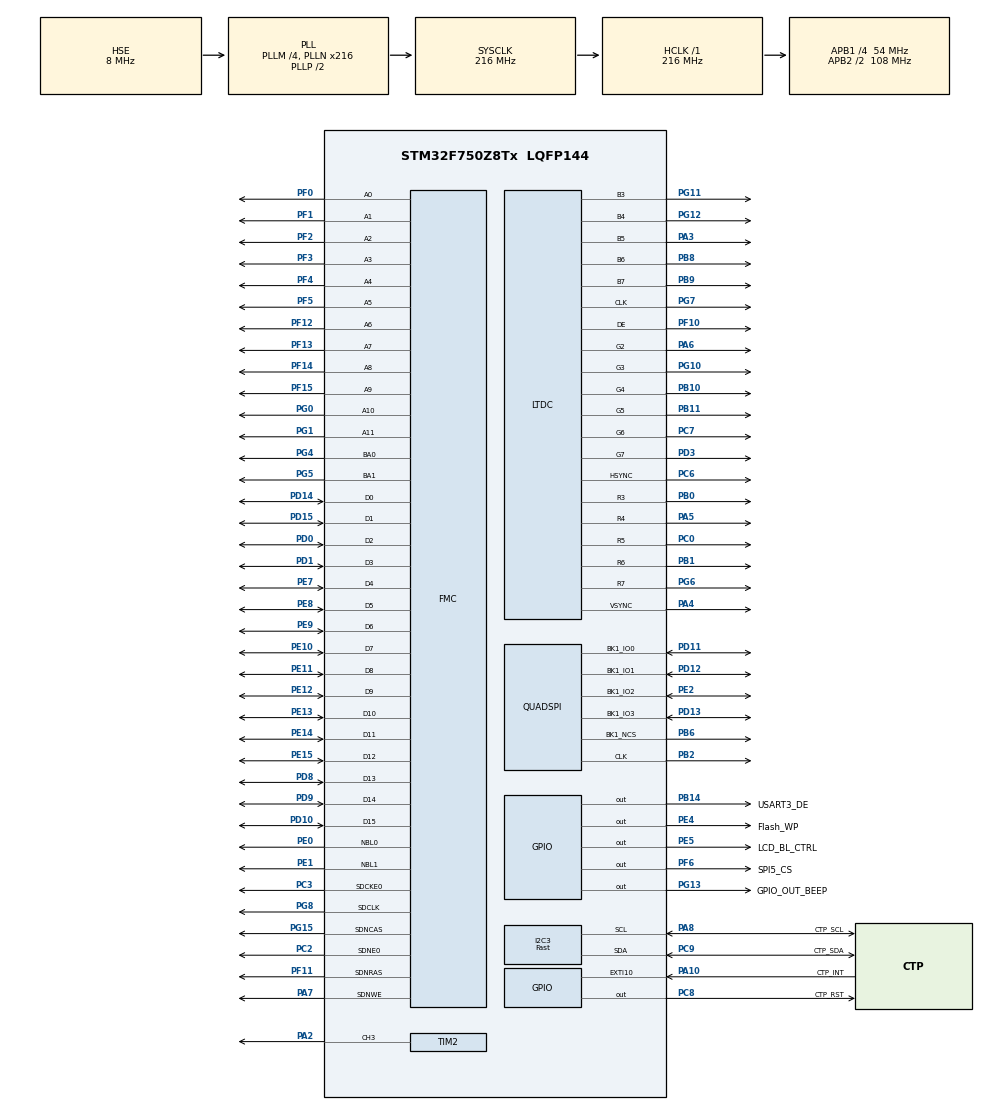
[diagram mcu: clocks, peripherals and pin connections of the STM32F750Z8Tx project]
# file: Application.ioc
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CORTEX_M7.ART_ACCLERATOR_ENABLE=1
CORTEX_M7.BaseAddress-Cortex_Memory_Protection_Unit_Region0_Settings=0xC0000000
CORTEX_M7.CPU_DCache=Enabled
CORTEX_M7.CPU_ICache=Enabled
CORTEX_M7.Enable-Cortex_Memory_Protection_Unit_Region0_Settings=MPU_REGION_ENABLE
CORTEX_M7.IsCacheable-Cortex_Memory_Protection_Unit_Region0_Settings=MPU_ACCESS_CACHEABLE
CORTEX_M7.IsShareable-Cortex_Memory_Protection_Unit_Region0_Settings=MPU_ACCESS_SHAREABLE
CORTEX_M7.MPU_Control=MPU_HFNMI_PRIVDEF
CORTEX_M7.Size-Cortex_Memory_Protection_Unit_Region0_Settings=MPU_REGION_SIZE_16MB
DMA2D.ColorMode=DMA2D_OUTPUT_RGB565
Dma.MEMTOMEM.1.Direction=DMA_MEMORY_TO_MEMORY
Dma.MEMTOMEM.1.FIFOMode=DMA_FIFOMODE_ENABLE
Dma.MEMTOMEM.1.FIFOThreshold=DMA_FIFO_THRESHOLD_FULL
Dma.MEMTOMEM.1.Instance=DMA2_Stream0
Dma.MEMTOMEM.1.MemBurst=DMA_MBURST_SINGLE
Dma.MEMTOMEM.1.MemDataAlignment=DMA_MDATAALIGN_BYTE
Dma.MEMTOMEM.1.MemInc=DMA_MINC_ENABLE
Dma.MEMTOMEM.1.Mode=DMA_NORMAL
Dma.MEMTOMEM.1.PeriphBurst=DMA_PBURST_SINGLE
Dma.MEMTOMEM.1.PeriphDataAlignment=DMA_PDATAALIGN_BYTE
Dma.MEMTOMEM.1.PeriphInc=DMA_PINC_ENABLE
Dma.MEMTOMEM.1.Priority=DMA_PRIORITY_LOW
Dma.QUADSPI.0.Direction=DMA_PERIPH_TO_MEMORY
Dma.QUADSPI.0.FIFOMode=DMA_FIFOMODE_DISABLE
Dma.QUADSPI.0.Instance=DMA2_Stream7
Dma.QUADSPI.0.MemDataAlignment=DMA_MDATAALIGN_BYTE
Dma.QUADSPI.0.MemInc=DMA_MINC_ENABLE
Dma.QUADSPI.0.Mode=DMA_NORMAL
Dma.QUADSPI.0.PeriphDataAlignment=DMA_PDATAALIGN_BYTE
Dma.QUADSPI.0.PeriphInc=DMA_PINC_DISABLE
Dma.QUADSPI.0.Priority=DMA_PRIORITY_HIGH
Dma.Request0=QUADSPI
Dma.Request1=MEMTOMEM
FMC.CASLatency1=FMC_SDRAM_CAS_LATENCY_3
FMC.ExitSelfRefreshDelay1=7
FMC.LoadToActiveDelay1=2
FMC.RCDDelay1=2
FMC.RPDelay1=2
FMC.RPDelay2=2
FMC.RowCycleDelay1=7
FMC.RowCycleDelay2=7
FMC.SelfRefreshTime1=4
FMC.WriteRecoveryTime1=3
FREERTOS.INCLUDE_vTaskDelayUntil=0
FREERTOS.Tasks01=defaultTask,24,4096,StartDefaultTask,Default,NULL,Dynamic,NULL,NULL
FREERTOS.configTOTAL_HEAP_SIZE=40960
FREERTOS.configUSE_IDLE_HOOK=0
FREERTOS.configUSE_TICK_HOOK=1
I2C3.I2C_Speed_Mode=I2C_Fast
I2C3.Timing=0x6000030D
LTDC.ActiveH=480
LTDC.ActiveW=800
LTDC.Alpha_L0=255
LTDC.DEPolarity=LTDC_DEPOLARITY_AL
LTDC.FBStartAdress_L0=0xC0500000
LTDC.HBP=8
LTDC.HFP=8
LTDC.HSync=4
LTDC.ImageHeight_L0=480
LTDC.ImageWidth_L0=800
LTDC.Layers=0
LTDC.PCPolarity=LTDC_PCPOLARITY_IPC
LTDC.PixelFormat_L0=LTDC_PIXEL_FORMAT_RGB565
LTDC.VBP=8
LTDC.VFP=8
LTDC.VSync=4
LTDC.WindowX1_L0=800
LTDC.WindowY1_L0=480
Mcu.Family=STM32F7
Mcu.Name=STM32F750Z8Tx
Mcu.Package=LQFP144
NVIC.DMA2D_IRQn=true\:5\:0\:true\:false\:true\:false\:true\:true
NVIC.DMA2_Stream7_IRQn=true\:5\:0\:true\:false\:true\:true\:false\:true
NVIC.I2C3_ER_IRQn=true\:5\:0\:true\:false\:true\:true\:true\:true
NVIC.I2C3_EV_IRQn=true\:5\:0\:true\:false\:true\:true\:true\:true
NVIC.LTDC_ER_IRQn=true\:5\:0\:true\:false\:true\:true\:true\:true
NVIC.LTDC_IRQn=true\:5\:0\:true\:false\:true\:true\:true\:true
NVIC.PriorityGroup=NVIC_PRIORITYGROUP_4
NVIC.TIM5_IRQn=true\:0\:0\:false\:false\:true\:false\:false\:true
NVIC.TIM7_IRQn=true\:5\:0\:true\:false\:true\:false\:true\:true
NVIC.TimeBase=TIM5_IRQn
NVIC.TimeBaseIP=TIM5
PA1.Signal=LTDC_R2
PA10.GPIO_Label=CTP_INT
PA10.Signal=GPXTI10
PA13.Mode=Serial_Wire
PA13.Signal=SYS_JTMS-SWDIO
PA14.Mode=Serial_Wire
PA14.Signal=SYS_JTCK-SWCLK
PA2.Signal=S_TIM2_CH3
PA3.GPIO_Speed=GPIO_SPEED_FREQ_VERY_HIGH
PA3.Mode=RGB565
PA3.Signal=LTDC_B5
PA4.GPIO_Speed=GPIO_SPEED_FREQ_VERY_HIGH
PA4.Mode=RGB565
PA4.Signal=LTDC_VSYNC
PA5.GPIO_Speed=GPIO_SPEED_FREQ_VERY_HIGH
PA5.Mode=RGB565
PA5.Signal=LTDC_R4
PA6.GPIO_Speed=GPIO_SPEED_FREQ_VERY_HIGH
PA6.Mode=RGB565
PA6.Signal=LTDC_G2
PA7.Signal=FMC_SDNWE
PA8.GPIO_Label=CTP_SCL
PA8.Mode=I2C
PA8.Signal=I2C3_SCL
PB0.GPIO_Speed=GPIO_SPEED_FREQ_VERY_HIGH
PB0.Mode=RGB565
PB0.Signal=LTDC_R3
PB1.GPIO_Speed=GPIO_SPEED_FREQ_VERY_HIGH
PB1.Mode=RGB565
PB1.Signal=LTDC_R6
PB10.GPIO_Speed=GPIO_SPEED_FREQ_VERY_HIGH
PB10.Mode=RGB565
PB10.Signal=LTDC_G4
PB11.GPIO_Speed=GPIO_SPEED_FREQ_VERY_HIGH
PB11.Mode=RGB565
PB11.Signal=LTDC_G5
PB14.GPIO_Label=USART3_DE
PB14.Signal=GPIO_Output
PB2.Mode=Single Bank 1
PB2.Signal=QUADSPI_CLK
PB6.Mode=Single Bank 1
PB6.Signal=QUADSPI_BK1_NCS
PB8.GPIO_Speed=GPIO_SPEED_FREQ_VERY_HIGH
PB8.Mode=RGB565
PB8.Signal=LTDC_B6
PB9.GPIO_Speed=GPIO_SPEED_FREQ_VERY_HIGH
PB9.Mode=RGB565
PB9.Signal=LTDC_B7
PC0.GPIO_Speed=GPIO_SPEED_FREQ_VERY_HIGH
PC0.Mode=RGB565
PC0.Signal=LTDC_R5
PC14/OSC32_IN.Mode=LSE-External-Oscillator
PC14/OSC32_IN.Signal=RCC_OSC32_IN
PC15/OSC32_OUT.Mode=LSE-External-Oscillator
PC15/OSC32_OUT.Signal=RCC_OSC32_OUT
PC2.Mode=SdramChipSelect1_1
PC2.Signal=FMC_SDNE0
PC3.Mode=SdramChipSelect1_1
PC3.Signal=FMC_SDCKE0
PC6.GPIO_Speed=GPIO_SPEED_FREQ_VERY_HIGH
PC6.Mode=RGB565
PC6.Signal=LTDC_HSYNC
PC7.GPIO_Speed=GPIO_SPEED_FREQ_VERY_HIGH
PC7.Mode=RGB565
PC7.Signal=LTDC_G6
PC8.GPIO_Label=CTP_RST
PC8.PinState=GPIO_PIN_SET
PC8.Signal=GPIO_Output
PC9.GPIO_Label=CTP_SDA
PC9.Mode=I2C
PC9.Signal=I2C3_SDA
PD0.Signal=FMC_D2_DA2
PD1.Signal=FMC_D3_DA3
PD10.Signal=FMC_D15_DA15
PD11.Mode=Single Bank 1
PD11.Signal=QUADSPI_BK1_IO0
PD12.Mode=Single Bank 1
PD12.Signal=QUADSPI_BK1_IO1
PD13.Mode=Single Bank 1
PD13.Signal=QUADSPI_BK1_IO3
PD14.Signal=FMC_D0_DA0
PD15.Signal=FMC_D1_DA1
PD3.GPIO_Speed=GPIO_SPEED_FREQ_VERY_HIGH
PD3.Mode=RGB565
PD3.Signal=LTDC_G7
PD6.Signal=LTDC_B2
PD8.Signal=FMC_D13_DA13
PD9.Signal=FMC_D14_DA14
PE0.Signal=FMC_NBL0
PE1.Signal=FMC_NBL1
PE10.Signal=FMC_D7_DA7
PE11.Signal=FMC_D8_DA8
PE12.Signal=FMC_D9_DA9
PE13.Signal=FMC_D10_DA10
PE14.Signal=FMC_D11_DA11
PE15.Signal=FMC_D12_DA12
PE2.Mode=Single Bank 1
PE2.Signal=QUADSPI_BK1_IO2
PE4.GPIO_Label=Flash_WP
PE4.PinState=GPIO_PIN_RESET
PE4.Signal=GPIO_Output
PE5.GPIO_Label=LCD_BL_CTRL
PE5.PinState=GPIO_PIN_RESET
PE5.Signal=GPIO_Output
PE7.Signal=FMC_D4_DA4
PE8.Signal=FMC_D5_DA5
PE9.Signal=FMC_D6_DA6
PF0.Signal=FMC_A0
PF1.Signal=FMC_A1
PF10.GPIO_PuPd=GPIO_NOPULL
PF10.GPIO_Speed=GPIO_SPEED_FREQ_VERY_HIGH
PF10.Mode=RGB565
PF10.Signal=LTDC_DE
PF11.Signal=FMC_SDNRAS
PF12.Signal=FMC_A6
PF13.Signal=FMC_A7
PF14.Signal=FMC_A8
PF15.Signal=FMC_A9
PF2.Signal=FMC_A2
PF3.Signal=FMC_A3
PF4.Signal=FMC_A4
PF5.Signal=FMC_A5
PF6.GPIO_Label=SPI5_CS
PF6.GPIO_Speed=GPIO_SPEED_FREQ_HIGH
PF6.Signal=GPIO_Output
PG0.Signal=FMC_A10
PG1.Signal=FMC_A11
PG10.GPIO_Speed=GPIO_SPEED_FREQ_VERY_HIGH
PG10.Mode=RGB565
PG10.Signal=LTDC_G3
PG11.GPIO_Speed=GPIO_SPEED_FREQ_VERY_HIGH
PG11.Mode=RGB565
PG11.Signal=LTDC_B3
PG12.GPIO_Speed=GPIO_SPEED_FREQ_VERY_HIGH
PG12.Mode=RGB565
PG12.Signal=LTDC_B4
PG13.GPIO_Label=GPIO_OUT_BEEP
PG13.Signal=GPIO_Output
PG15.Signal=FMC_SDNCAS
PG4.Signal=FMC_A14_BA0
PG5.Signal=FMC_A15_BA1
PG6.GPIO_Speed=GPIO_SPEED_FREQ_VERY_HIGH
PG6.Mode=RGB565
PG6.Signal=LTDC_R7
PG7.GPIO_Speed=GPIO_SPEED_FREQ_VERY_HIGH
PG7.Mode=RGB565
PG7.Signal=LTDC_CLK
PG8.Signal=FMC_SDCLK
PH0/OSC_IN.Mode=HSE-External-Oscillator
PH0/OSC_IN.Signal=RCC_OSC_IN
PH1/OSC_OUT.Mode=HSE-External-Oscillator
PH1/OSC_OUT.Signal=RCC_OSC_OUT
ProjectManager.HeapSize=0x1000
ProjectManager.StackSize=0x1000
ProjectManager.TargetToolchain=STM32CubeIDE
QUADSPI.ChipSelectHighTime=QSPI_CS_HIGH_TIME_2_CYCLE
QUADSPI.ClockPrescaler=3
QUADSPI.FifoThreshold=4
QUADSPI.FlashSize=16
QUADSPI.SampleShifting=QSPI_SAMPLE_SHIFTING_HALFCYCLE
RCC.AHBFreq_Value=216000000
RCC.APB1CLKDivider=RCC_HCLK_DIV4
RCC.APB1Freq_Value=54000000
RCC.APB1TimFreq_Value=108000000
RCC.APB2CLKDivider=RCC_HCLK_DIV2
RCC.APB2Freq_Value=108000000
RCC.APB2TimFreq_Value=216000000
RCC.CortexFreq_Value=216000000
RCC.HCLKFreq_Value=216000000
RCC.HSE_VALUE=8000000
RCC.HSI_VALUE=16000000
RCC.PLLM=4
RCC.PLLN=216
RCC.PLLSAIN=69
RCC.PLLSAIR=3
RCC.PLLSourceVirtual=RCC_PLLSOURCE_HSE
RCC.RTCClockSelection=RCC_RTCCLKSOURCE_LSE
RCC.SYSCLKFreq_VALUE=216000000
RCC.SYSCLKSource=RCC_SYSCLKSOURCE_PLLCLK
RCC.USBFreq_Value=216000000
RCC.VCOOutputFreq_Value=432000000
SH.FMC_A0.0=FMC_A0,12b-sda1
SH.FMC_A1.0=FMC_A1,12b-sda1
SH.FMC_A10.0=FMC_A10,12b-sda1
SH.FMC_A11.0=FMC_A11,12b-sda1
SH.FMC_A14_BA0.0=FMC_BA0,FourSdramBanks1
SH.FMC_A15_BA1.0=FMC_BA1,FourSdramBanks1
SH.FMC_A2.0=FMC_A2,12b-sda1
SH.FMC_A3.0=FMC_A3,12b-sda1
SH.FMC_A4.0=FMC_A4,12b-sda1
SH.FMC_A5.0=FMC_A5,12b-sda1
SH.FMC_A6.0=FMC_A6,12b-sda1
SH.FMC_A7.0=FMC_A7,12b-sda1
SH.FMC_A8.0=FMC_A8,12b-sda1
SH.FMC_A9.0=FMC_A9,12b-sda1
SH.FMC_D0_DA0.0=FMC_D0,sd-16b-d1
SH.FMC_D10_DA10.0=FMC_D10,sd-16b-d1
SH.FMC_D11_DA11.0=FMC_D11,sd-16b-d1
SH.FMC_D12_DA12.0=FMC_D12,sd-16b-d1
SH.FMC_D13_DA13.0=FMC_D13,sd-16b-d1
SH.FMC_D14_DA14.0=FMC_D14,sd-16b-d1
SH.FMC_D15_DA15.0=FMC_D15,sd-16b-d1
SH.FMC_D1_DA1.0=FMC_D1,sd-16b-d1
SH.FMC_D2_DA2.0=FMC_D2,sd-16b-d1
SH.FMC_D3_DA3.0=FMC_D3,sd-16b-d1
SH.FMC_D4_DA4.0=FMC_D4,sd-16b-d1
SH.FMC_D5_DA5.0=FMC_D5,sd-16b-d1
SH.FMC_D6_DA6.0=FMC_D6,sd-16b-d1
SH.FMC_D7_DA7.0=FMC_D7,sd-16b-d1
SH.FMC_D8_DA8.0=FMC_D8,sd-16b-d1
SH.FMC_D9_DA9.0=FMC_D9,sd-16b-d1
SH.FMC_NBL0.0=FMC_NBL0,Sd2ByteEnable1
SH.FMC_NBL1.0=FMC_NBL1,Sd2ByteEnable1
SH.FMC_SDCLK.0=FMC_SDCLK,12b-sda1
SH.FMC_SDNCAS.0=FMC_SDNCAS,12b-sda1
SH.FMC_SDNRAS.0=FMC_SDNRAS,12b-sda1
SH.FMC_SDNWE.0=FMC_SDNWE,12b-sda1
SH.S_TIM2_CH3.0=TIM2_CH3,PWM Generation3 CH3
STMicroelectronics.X-CUBE-TOUCHGFX.4.16.0.ApplicationCcGraphicsJjApplication=TouchGFXOoGenerator
STMicroelectronics.X-CUBE-TOUCHGFX.4.16.0.tgfx_address1=0xc0500000
STMicroelectronics.X-CUBE-TOUCHGFX.4.16.0.tgfx_address2=0xc05bb800
STMicroelectronics.X-CUBE-TOUCHGFX.4.16.0.tgfx_buffering_strategy=Double
STMicroelectronics.X-CUBE-TOUCHGFX.4.16.0.tgfx_custom_height=128
STMicroelectronics.X-CUBE-TOUCHGFX.4.16.0.tgfx_display_interface=disp_ltdc
STMicroelectronics.X-CUBE-TOUCHGFX.4.16.0.tgfx_hardware_accelerator=dma_2d
STMicroelectronics.X-CUBE-TOUCHGFX.4.16.0.tgfx_location=By Address
STMicroelectronics.X-CUBE-TOUCHGFX.4.16.0.tgfx_vsync=vsync_ltdc
TIM2.AutoReloadPreload=TIM_AUTORELOAD_PRELOAD_ENABLE
TIM2.Channel-PWM\ Generation3\ CH3=TIM_CHANNEL_3
TIM2.Period=99
TIM2.Prescaler=54-1
TIM7.Period=0
VP_CRC_VS_CRC.Mode=CRC_Activate
VP_DMA2D_VS_DMA2D.Mode=DMA2D_Activate
VP_FREERTOS_VS_CMSIS_V2.Mode=CMSIS_V2
VP_STMicroelectronics.X-CUBE-TOUCHGFX_VS_GraphicsJjApplication_4.16.0.Mode=GraphicsJjApplication
VP_SYS_VS_tim5.Mode=TIM5
VP_TIM7_VS_ClockSourceINT.Mode=Enable_Timer
board=custom

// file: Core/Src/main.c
/* USER CODE BEGIN Header */
/**
  ******************************************************************************
  * @file           : main.c
  * @brief          : Main program body
  ******************************************************************************
  * @attention
  *
  * <h2><center>&copy; Copyright (c) 2023 STMicroelectronics.
  * All rights reserved.</center></h2>
  *
  * This software component is licensed by ST under Ultimate Liberty license
  * SLA0044, the "License"; You may not use this file except in compliance with
  * the License. You may obtain a copy of the License at:
  *                             www.st.com/SLA0044
  *
  ******************************************************************************
  */
/* USER CODE END Header */
#include "main.h"
#include "cmsis_os.h"
#include "app_touchgfx.h"

/* USER CODE BEGIN PD */
#define ADDR_DISPLAY_MEM    ((uint32_t)0xC0500000)
/* USER CODE END PD */

CRC_HandleTypeDef hcrc;

DMA2D_HandleTypeDef hdma2d;

I2C_HandleTypeDef hi2c3;

LTDC_HandleTypeDef hltdc;

QSPI_HandleTypeDef hqspi;
DMA_HandleTypeDef hdma_quadspi;

TIM_HandleTypeDef htim2;
TIM_HandleTypeDef htim7;

DMA_HandleTypeDef hdma_memtomem_dma2_stream0;
SDRAM_HandleTypeDef hsdram1;

/* Definitions for defaultTask */
osThreadId_t defaultTaskHandle;
const osThreadAttr_t defaultTask_attributes = {
  .name = "defaultTask",
  .priority = (osPriority_t) osPriorityNormal,
  .stack_size = 4096 * 4
};

void SystemClock_Config(void);
static void MPU_Config(void);
static void MX_GPIO_Init(void);
static void MX_DMA_Init(void);
static void MX_QUADSPI_Init(void);
static void MX_DMA2D_Init(void);
static void MX_LTDC_Init(void);
static void MX_CRC_Init(void);
static void MX_FMC_Init(void);
static void MX_TIM7_Init(void);
static void MX_I2C3_Init(void);
static void MX_TIM2_Init(void);
void StartDefaultTask(void *argument);

/* USER CODE BEGIN 0 */
void Reset_Ressource(void)
{
  /*DeInit LCD Ressource*/
  __HAL_RCC_LTDC_CLK_DISABLE();
  __HAL_RCC_LTDC_FORCE_RESET();
  __HAL_RCC_LTDC_RELEASE_RESET();
  __HAL_RCC_PLLSAI_DISABLE();
  RCC->DCKCFGR1 = 0;
  RCC->PLLSAICFGR &= 0x0FFFFFFF;
  RCC->PLLSAICFGR |= 0x20000000;
}
/* USER CODE END 0 */

int main(void)
{
  /* USER CODE BEGIN 1 */
	memset((void *)ADDR_DISPLAY_MEM, 0x00, 800*480*2); //RESET
	Reset_Ressource();
  /* USER CODE END 1 */

  /* MPU Configuration--------------------------------------------------------*/
  MPU_Config();

  /* Enable I-Cache---------------------------------------------------------*/
  SCB_EnableICache();

  /* Enable D-Cache---------------------------------------------------------*/
  SCB_EnableDCache();

  /* MCU Configuration--------------------------------------------------------*/

  /* Reset of all peripherals, Initializes the Flash interface and the Systick. */
  HAL_Init();

  /* Configure the system clock */
  SystemClock_Config();

  /* Initialize all configured peripherals */
  MX_GPIO_Init();
  MX_DMA_Init();
  MX_QUADSPI_Init();
  MX_DMA2D_Init();
  MX_LTDC_Init();
  MX_CRC_Init();
  MX_FMC_Init();
  MX_TIM7_Init();
  MX_I2C3_Init();
  MX_TIM2_Init();
  MX_TouchGFX_Init();
  /* USER CODE BEGIN 2 */
  memset((void *)ADDR_DISPLAY_MEM, 0x00, 800*480*2); //RESET
  HAL_GPIO_WritePin(GPIOE, Flash_WP_Pin|LCD_BL_CTRL_Pin, GPIO_PIN_SET);
  /* USER CODE END 2 */

  /* Init scheduler */
  osKernelInitialize();

  /* Create the thread(s) */
  /* creation of defaultTask */
  defaultTaskHandle = osThreadNew(StartDefaultTask, NULL, &defaultTask_attributes);

  /* Start scheduler */
  osKernelStart();

  /* We should never get here as control is now taken by the scheduler */
  /* Infinite loop */
  while (1)
  {

  }
}

void SystemClock_Config(void)
{
  RCC_OscInitTypeDef RCC_OscInitStruct = {0};
  RCC_ClkInitTypeDef RCC_ClkInitStruct = {0};
  RCC_PeriphCLKInitTypeDef PeriphClkInitStruct = {0};

  /** Configure LSE Drive Capability
  */
  HAL_PWR_EnableBkUpAccess();
  /** Configure the main internal regulator output voltage
  */
  __HAL_RCC_PWR_CLK_ENABLE();
  __HAL_PWR_VOLTAGESCALING_CONFIG(PWR_REGULATOR_VOLTAGE_SCALE1);
  /** Initializes the RCC Oscillators according to the specified parameters
  * in the RCC_OscInitTypeDef structure.
  */
  RCC_OscInitStruct.OscillatorType = RCC_OSCILLATORTYPE_HSE;
  RCC_OscInitStruct.HSEState = RCC_HSE_ON;
  RCC_OscInitStruct.PLL.PLLState = RCC_PLL_ON;
  RCC_OscInitStruct.PLL.PLLSource = RCC_PLLSOURCE_HSE;
  RCC_OscInitStruct.PLL.PLLM = 4;
  RCC_OscInitStruct.PLL.PLLN = 216;
  RCC_OscInitStruct.PLL.PLLP = RCC_PLLP_DIV2;
  RCC_OscInitStruct.PLL.PLLQ = 2;
  if (HAL_RCC_OscConfig(&RCC_OscInitStruct) != HAL_OK)
  {
    Error_Handler();
  }
  /** Activate the Over-Drive mode
  */
  if (HAL_PWREx_EnableOverDrive() != HAL_OK)
  {
    Error_Handler();
  }
  /** Initializes the CPU, AHB and APB buses clocks
  */
  RCC_ClkInitStruct.ClockType = RCC_CLOCKTYPE_HCLK|RCC_CLOCKTYPE_SYSCLK
                              |RCC_CLOCKTYPE_PCLK1|RCC_CLOCKTYPE_PCLK2;
  RCC_ClkInitStruct.SYSCLKSource = RCC_SYSCLKSOURCE_PLLCLK;
  RCC_ClkInitStruct.AHBCLKDivider = RCC_SYSCLK_DIV1;
  RCC_ClkInitStruct.APB1CLKDivider = RCC_HCLK_DIV4;
  RCC_ClkInitStruct.APB2CLKDivider = RCC_HCLK_DIV2;

  if (HAL_RCC_ClockConfig(&RCC_ClkInitStruct, FLASH_LATENCY_7) != HAL_OK)
  {
    Error_Handler();
  }
  PeriphClkInitStruct.PeriphClockSelection = RCC_PERIPHCLK_LTDC|RCC_PERIPHCLK_I2C3;
  PeriphClkInitStruct.PLLSAI.PLLSAIN = 69;
  PeriphClkInitStruct.PLLSAI.PLLSAIR = 3;
  PeriphClkInitStruct.PLLSAI.PLLSAIQ = 2;
  PeriphClkInitStruct.PLLSAI.PLLSAIP = RCC_PLLSAIP_DIV2;
  PeriphClkInitStruct.PLLSAIDivQ = 1;
  PeriphClkInitStruct.PLLSAIDivR = RCC_PLLSAIDIVR_2;
  PeriphClkInitStruct.I2c3ClockSelection = RCC_I2C3CLKSOURCE_PCLK1;
  if (HAL_RCCEx_PeriphCLKConfig(&PeriphClkInitStruct) != HAL_OK)
  {
    Error_Handler();
  }
}

static void MX_CRC_Init(void)
{

  hcrc.Instance = CRC;
  hcrc.Init.DefaultPolynomialUse = DEFAULT_POLYNOMIAL_ENABLE;
  hcrc.Init.DefaultInitValueUse = DEFAULT_INIT_VALUE_ENABLE;
  hcrc.Init.InputDataInversionMode = CRC_INPUTDATA_INVERSION_NONE;
  hcrc.Init.OutputDataInversionMode = CRC_OUTPUTDATA_INVERSION_DISABLE;
  hcrc.InputDataFormat = CRC_INPUTDATA_FORMAT_BYTES;
  if (HAL_CRC_Init(&hcrc) != HAL_OK)
  {
    Error_Handler();
  }

}

static void MX_DMA2D_Init(void)
{

  hdma2d.Instance = DMA2D;
  hdma2d.Init.Mode = DMA2D_M2M;
  hdma2d.Init.ColorMode = DMA2D_OUTPUT_RGB565;
  hdma2d.Init.OutputOffset = 0;
  hdma2d.LayerCfg[1].InputOffset = 0;
  hdma2d.LayerCfg[1].InputColorMode = DMA2D_INPUT_RGB565;
  hdma2d.LayerCfg[1].AlphaMode = DMA2D_NO_MODIF_ALPHA;
  hdma2d.LayerCfg[1].InputAlpha = 0;
  if (HAL_DMA2D_Init(&hdma2d) != HAL_OK)
  {
    Error_Handler();
  }
  if (HAL_DMA2D_ConfigLayer(&hdma2d, 1) != HAL_OK)
  {
    Error_Handler();
  }

}

static void MX_I2C3_Init(void)
{

  hi2c3.Instance = I2C3;
  hi2c3.Init.Timing = 0x6000030D;
  hi2c3.Init.OwnAddress1 = 0;
  hi2c3.Init.AddressingMode = I2C_ADDRESSINGMODE_7BIT;
  hi2c3.Init.DualAddressMode = I2C_DUALADDRESS_DISABLE;
  hi2c3.Init.OwnAddress2 = 0;
  hi2c3.Init.OwnAddress2Masks = I2C_OA2_NOMASK;
  hi2c3.Init.GeneralCallMode = I2C_GENERALCALL_DISABLE;
  hi2c3.Init.NoStretchMode = I2C_NOSTRETCH_DISABLE;
  if (HAL_I2C_Init(&hi2c3) != HAL_OK)
  {
    Error_Handler();
  }
  /** Configure Analogue filter
  */
  if (HAL_I2CEx_ConfigAnalogFilter(&hi2c3, I2C_ANALOGFILTER_ENABLE) != HAL_OK)
  {
    Error_Handler();
  }
  /** Configure Digital filter
  */
  if (HAL_I2CEx_ConfigDigitalFilter(&hi2c3, 0) != HAL_OK)
  {
    Error_Handler();
  }

}

static void MX_LTDC_Init(void)
{

  LTDC_LayerCfgTypeDef pLayerCfg = {0};
  LTDC_LayerCfgTypeDef pLayerCfg1 = {0};

  hltdc.Instance = LTDC;
  hltdc.Init.HSPolarity = LTDC_HSPOLARITY_AL;
  hltdc.Init.VSPolarity = LTDC_VSPOLARITY_AL;
  hltdc.Init.DEPolarity = LTDC_DEPOLARITY_AL;
  hltdc.Init.PCPolarity = LTDC_PCPOLARITY_IPC;
  hltdc.Init.HorizontalSync = 3;
  hltdc.Init.VerticalSync = 3;
  hltdc.Init.AccumulatedHBP = 11;
  hltdc.Init.AccumulatedVBP = 11;
  hltdc.Init.AccumulatedActiveW = 811;
  hltdc.Init.AccumulatedActiveH = 491;
  hltdc.Init.TotalWidth = 819;
  hltdc.Init.TotalHeigh = 499;
  hltdc.Init.Backcolor.Blue = 0;
  hltdc.Init.Backcolor.Green = 0;
  hltdc.Init.Backcolor.Red = 0;
  if (HAL_LTDC_Init(&hltdc) != HAL_OK)
  {
    Error_Handler();
  }
  pLayerCfg.WindowX0 = 0;
  pLayerCfg.WindowX1 = 800;
  pLayerCfg.WindowY0 = 0;
  pLayerCfg.WindowY1 = 480;
  pLayerCfg.PixelFormat = LTDC_PIXEL_FORMAT_RGB565;
  pLayerCfg.Alpha = 255;
  pLayerCfg.Alpha0 = 0;
  pLayerCfg.BlendingFactor1 = LTDC_BLENDING_FACTOR1_CA;
  pLayerCfg.BlendingFactor2 = LTDC_BLENDING_FACTOR2_CA;
  pLayerCfg.FBStartAdress = 0xC0500000;
  pLayerCfg.ImageWidth = 800;
  pLayerCfg.ImageHeight = 480;
  pLayerCfg.Backcolor.Blue = 0;
  pLayerCfg.Backcolor.Green = 0;
  pLayerCfg.Backcolor.Red = 0;
  if (HAL_LTDC_ConfigLayer(&hltdc, &pLayerCfg, 0) != HAL_OK)
  {
    Error_Handler();
  }
  pLayerCfg1.WindowX0 = 0;
  pLayerCfg1.WindowX1 = 0;
  pLayerCfg1.WindowY0 = 0;
  pLayerCfg1.WindowY1 = 0;
  pLayerCfg1.Alpha = 0;
  pLayerCfg1.Alpha0 = 0;
  pLayerCfg1.BlendingFactor1 = LTDC_BLENDING_FACTOR1_CA;
  pLayerCfg1.BlendingFactor2 = LTDC_BLENDING_FACTOR2_CA;
  pLayerCfg1.FBStartAdress = 0;
  pLayerCfg1.ImageWidth = 0;
  pLayerCfg1.ImageHeight = 0;
  pLayerCfg1.Backcolor.Blue = 0;
  pLayerCfg1.Backcolor.Green = 0;
  pLayerCfg1.Backcolor.Red = 0;
  if (HAL_LTDC_ConfigLayer(&hltdc, &pLayerCfg1, 1) != HAL_OK)
  {
    Error_Handler();
  }

}

static void MX_QUADSPI_Init(void)
{

  /* USER CODE BEGIN QUADSPI_Init 0 */
	return;
  /* USER CODE END QUADSPI_Init 0 */

  /* QUADSPI parameter configuration*/
  hqspi.Instance = QUADSPI;
  hqspi.Init.ClockPrescaler = 3;
  hqspi.Init.FifoThreshold = 4;
  hqspi.Init.SampleShifting = QSPI_SAMPLE_SHIFTING_HALFCYCLE;
  hqspi.Init.FlashSize = 16;
  hqspi.Init.ChipSelectHighTime = QSPI_CS_HIGH_TIME_2_CYCLE;
  hqspi.Init.ClockMode = QSPI_CLOCK_MODE_0;
  hqspi.Init.FlashID = QSPI_FLASH_ID_1;
  hqspi.Init.DualFlash = QSPI_DUALFLASH_DISABLE;
  if (HAL_QSPI_Init(&hqspi) != HAL_OK)
  {
    Error_Handler();
  }

}

static void MX_TIM2_Init(void)
{

  TIM_MasterConfigTypeDef sMasterConfig = {0};
  TIM_OC_InitTypeDef sConfigOC = {0};

  htim2.Instance = TIM2;
  htim2.Init.Prescaler = 54-1;
  htim2.Init.CounterMode = TIM_COUNTERMODE_UP;
  htim2.Init.Period = 99;
  htim2.Init.ClockDivision = TIM_CLOCKDIVISION_DIV1;
  htim2.Init.AutoReloadPreload = TIM_AUTORELOAD_PRELOAD_ENABLE;
  if (HAL_TIM_PWM_Init(&htim2) != HAL_OK)
  {
    Error_Handler();
  }
  sMasterConfig.MasterOutputTrigger = TIM_TRGO_RESET;
  sMasterConfig.MasterSlaveMode = TIM_MASTERSLAVEMODE_DISABLE;
  if (HAL_TIMEx_MasterConfigSynchronization(&htim2, &sMasterConfig) != HAL_OK)
  {
    Error_Handler();
  }
  sConfigOC.OCMode = TIM_OCMODE_PWM1;
  sConfigOC.Pulse = 0;
  sConfigOC.OCPolarity = TIM_OCPOLARITY_HIGH;
  sConfigOC.OCFastMode = TIM_OCFAST_DISABLE;
  if (HAL_TIM_PWM_ConfigChannel(&htim2, &sConfigOC, TIM_CHANNEL_3) != HAL_OK)
  {
    Error_Handler();
  }
  HAL_TIM_MspPostInit(&htim2);

}

static void MX_TIM7_Init(void)
{

  /* USER CODE BEGIN TIM7_Init 0 */
	return;
  /* USER CODE END TIM7_Init 0 */

  TIM_MasterConfigTypeDef sMasterConfig = {0};

  htim7.Instance = TIM7;
  htim7.Init.Prescaler = 0;
  htim7.Init.CounterMode = TIM_COUNTERMODE_UP;
  htim7.Init.Period = 0;
  htim7.Init.AutoReloadPreload = TIM_AUTORELOAD_PRELOAD_DISABLE;
  if (HAL_TIM_Base_Init(&htim7) != HAL_OK)
  {
    Error_Handler();
  }
  sMasterConfig.MasterOutputTrigger = TIM_TRGO_RESET;
  sMasterConfig.MasterSlaveMode = TIM_MASTERSLAVEMODE_DISABLE;
  if (HAL_TIMEx_MasterConfigSynchronization(&htim7, &sMasterConfig) != HAL_OK)
  {
    Error_Handler();
  }

}

static void MX_DMA_Init(void)
{

  /* DMA controller clock enable */
  __HAL_RCC_DMA2_CLK_ENABLE();

  /* Configure DMA request hdma_memtomem_dma2_stream0 on DMA2_Stream0 */
  hdma_memtomem_dma2_stream0.Instance = DMA2_Stream0;
  hdma_memtomem_dma2_stream0.Init.Channel = DMA_CHANNEL_0;
  hdma_memtomem_dma2_stream0.Init.Direction = DMA_MEMORY_TO_MEMORY;
  hdma_memtomem_dma2_stream0.Init.PeriphInc = DMA_PINC_ENABLE;
  hdma_memtomem_dma2_stream0.Init.MemInc = DMA_MINC_ENABLE;
  hdma_memtomem_dma2_stream0.Init.PeriphDataAlignment = DMA_PDATAALIGN_BYTE;
  hdma_memtomem_dma2_stream0.Init.MemDataAlignment = DMA_MDATAALIGN_BYTE;
  hdma_memtomem_dma2_stream0.Init.Mode = DMA_NORMAL;
  hdma_memtomem_dma2_stream0.Init.Priority = DMA_PRIORITY_LOW;
  hdma_memtomem_dma2_stream0.Init.FIFOMode = DMA_FIFOMODE_ENABLE;
  hdma_memtomem_dma2_stream0.Init.FIFOThreshold = DMA_FIFO_THRESHOLD_FULL;
  hdma_memtomem_dma2_stream0.Init.MemBurst = DMA_MBURST_SINGLE;
  hdma_memtomem_dma2_stream0.Init.PeriphBurst = DMA_PBURST_SINGLE;
  if (HAL_DMA_Init(&hdma_memtomem_dma2_stream0) != HAL_OK)
  {
    Error_Handler( );
  }

  /* DMA interrupt init */
  /* DMA2_Stream7_IRQn interrupt configuration */
  HAL_NVIC_SetPriority(DMA2_Stream7_IRQn, 5, 0);
  HAL_NVIC_EnableIRQ(DMA2_Stream7_IRQn);

}

/* FMC initialization function */
static void MX_FMC_Init(void)
{

  /* USER CODE BEGIN FMC_Init 0 */
	return;
  /* USER CODE END FMC_Init 0 */

  FMC_SDRAM_TimingTypeDef SdramTiming = {0};

  /** Perform the SDRAM1 memory initialization sequence
  */
  hsdram1.Instance = FMC_SDRAM_DEVICE;
  /* hsdram1.Init */
  hsdram1.Init.SDBank = FMC_SDRAM_BANK1;
  hsdram1.Init.ColumnBitsNumber = FMC_SDRAM_COLUMN_BITS_NUM_8;
  hsdram1.Init.RowBitsNumber = FMC_SDRAM_ROW_BITS_NUM_12;
  hsdram1.Init.MemoryDataWidth = FMC_SDRAM_MEM_BUS_WIDTH_16;
  hsdram1.Init.InternalBankNumber = FMC_SDRAM_INTERN_BANKS_NUM_4;
  hsdram1.Init.CASLatency = FMC_SDRAM_CAS_LATENCY_3;
  hsdram1.Init.WriteProtection = FMC_SDRAM_WRITE_PROTECTION_DISABLE;
  hsdram1.Init.SDClockPeriod = FMC_SDRAM_CLOCK_DISABLE;
  hsdram1.Init.ReadBurst = FMC_SDRAM_RBURST_DISABLE;
  hsdram1.Init.ReadPipeDelay = FMC_SDRAM_RPIPE_DELAY_0;
  /* SdramTiming */
  SdramTiming.LoadToActiveDelay = 2;
  SdramTiming.ExitSelfRefreshDelay = 7;
  SdramTiming.SelfRefreshTime = 4;
  SdramTiming.RowCycleDelay = 7;
  SdramTiming.WriteRecoveryTime = 3;
  SdramTiming.RPDelay = 2;
  SdramTiming.RCDDelay = 2;

  if (HAL_SDRAM_Init(&hsdram1, &SdramTiming) != HAL_OK)
  {
    Error_Handler( );
  }

}

static void MX_GPIO_Init(void)
{
  GPIO_InitTypeDef GPIO_InitStruct = {0};

  /* GPIO Ports Clock Enable */
  __HAL_RCC_GPIOE_CLK_ENABLE();
  __HAL_RCC_GPIOC_CLK_ENABLE();
  __HAL_RCC_GPIOF_CLK_ENABLE();
  __HAL_RCC_GPIOH_CLK_ENABLE();
  __HAL_RCC_GPIOA_CLK_ENABLE();
  __HAL_RCC_GPIOB_CLK_ENABLE();
  __HAL_RCC_GPIOG_CLK_ENABLE();
  __HAL_RCC_GPIOD_CLK_ENABLE();

  /*Configure GPIO pin Output Level */
  HAL_GPIO_WritePin(GPIOE, Flash_WP_Pin|LCD_BL_CTRL_Pin, GPIO_PIN_RESET);

  /*Configure GPIO pin Output Level */
  HAL_GPIO_WritePin(SPI5_CS_GPIO_Port, SPI5_CS_Pin, GPIO_PIN_RESET);

  /*Configure GPIO pin Output Level */
  HAL_GPIO_WritePin(USART3_DE_GPIO_Port, USART3_DE_Pin, GPIO_PIN_RESET);

  /*Configure GPIO pin Output Level */
  HAL_GPIO_WritePin(CTP_RST_GPIO_Port, CTP_RST_Pin, GPIO_PIN_SET);

  /*Configure GPIO pin Output Level */
  HAL_GPIO_WritePin(GPIO_OUT_BEEP_GPIO_Port, GPIO_OUT_BEEP_Pin, GPIO_PIN_RESET);

  /*Configure GPIO pins : Flash_WP_Pin LCD_BL_CTRL_Pin */
  GPIO_InitStruct.Pin = Flash_WP_Pin|LCD_BL_CTRL_Pin;
  GPIO_InitStruct.Mode = GPIO_MODE_OUTPUT_PP;
  GPIO_InitStruct.Pull = GPIO_NOPULL;
  GPIO_InitStruct.Speed = GPIO_SPEED_FREQ_LOW;
  HAL_GPIO_Init(GPIOE, &GPIO_InitStruct);

  /*Configure GPIO pin : SPI5_CS_Pin */
  GPIO_InitStruct.Pin = SPI5_CS_Pin;
  GPIO_InitStruct.Mode = GPIO_MODE_OUTPUT_PP;
  GPIO_InitStruct.Pull = GPIO_NOPULL;
  GPIO_InitStruct.Speed = GPIO_SPEED_FREQ_HIGH;
  HAL_GPIO_Init(SPI5_CS_GPIO_Port, &GPIO_InitStruct);

  /*Configure GPIO pin : USART3_DE_Pin */
  GPIO_InitStruct.Pin = USART3_DE_Pin;
  GPIO_InitStruct.Mode = GPIO_MODE_OUTPUT_PP;
  GPIO_InitStruct.Pull = GPIO_NOPULL;
  GPIO_InitStruct.Speed = GPIO_SPEED_FREQ_LOW;
  HAL_GPIO_Init(USART3_DE_GPIO_Port, &GPIO_InitStruct);

  /*Configure GPIO pin : CTP_RST_Pin */
  GPIO_InitStruct.Pin = CTP_RST_Pin;
  GPIO_InitStruct.Mode = GPIO_MODE_OUTPUT_PP;
  GPIO_InitStruct.Pull = GPIO_NOPULL;
  GPIO_InitStruct.Speed = GPIO_SPEED_FREQ_LOW;
  HAL_GPIO_Init(CTP_RST_GPIO_Port, &GPIO_InitStruct);

  /*Configure GPIO pin : CTP_INT_Pin */
  GPIO_InitStruct.Pin = CTP_INT_Pin;
  GPIO_InitStruct.Mode = GPIO_MODE_IT_RISING;
  GPIO_InitStruct.Pull = GPIO_NOPULL;
  HAL_GPIO_Init(CTP_INT_GPIO_Port, &GPIO_InitStruct);

  /*Configure GPIO pin : GPIO_OUT_BEEP_Pin */
  GPIO_InitStruct.Pin = GPIO_OUT_BEEP_Pin;
  GPIO_InitStruct.Mode = GPIO_MODE_OUTPUT_PP;
  GPIO_InitStruct.Pull = GPIO_NOPULL;
  GPIO_InitStruct.Speed = GPIO_SPEED_FREQ_LOW;
  HAL_GPIO_Init(GPIO_OUT_BEEP_GPIO_Port, &GPIO_InitStruct);

}

void StartDefaultTask(void *argument)
{
  /* USER CODE BEGIN 5 */
	MX_TouchGFX_Process();
  /* Infinite loop */
  for(;;)
  {
    osDelay(1);
  }
  /* USER CODE END 5 */
}

/* MPU Configuration */

void MPU_Config(void)
{
  MPU_Region_InitTypeDef MPU_InitStruct = {0};
  return;
  /* Disables the MPU */
  HAL_MPU_Disable();
  /** Initializes and configures the Region and the memory to be protected
  */
  MPU_InitStruct.Enable = MPU_REGION_ENABLE;
  MPU_InitStruct.Number = MPU_REGION_NUMBER0;
  MPU_InitStruct.BaseAddress = 0xC0000000;
  MPU_InitStruct.Size = MPU_REGION_SIZE_16MB;
  MPU_InitStruct.SubRegionDisable = 0x0;
  MPU_InitStruct.TypeExtField = MPU_TEX_LEVEL0;
  MPU_InitStruct.AccessPermission = MPU_REGION_NO_ACCESS;
  MPU_InitStruct.DisableExec = MPU_INSTRUCTION_ACCESS_ENABLE;
  MPU_InitStruct.IsShareable = MPU_ACCESS_SHAREABLE;
  MPU_InitStruct.IsCacheable = MPU_ACCESS_CACHEABLE;
  MPU_InitStruct.IsBufferable = MPU_ACCESS_NOT_BUFFERABLE;

  HAL_MPU_ConfigRegion(&MPU_InitStruct);
  /* Enables the MPU */
  HAL_MPU_Enable(MPU_HFNMI_PRIVDEF);

}
void HAL_TIM_PeriodElapsedCallback(TIM_HandleTypeDef *htim)
{
  if (htim->Instance == TIM5) {
    HAL_IncTick();
  }
}

void Error_Handler(void)
{
}

/************************ (C) COPYRIGHT STMicroelectronics *****END OF FILE****/

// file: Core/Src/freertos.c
/* USER CODE BEGIN Header */
/**
  ******************************************************************************
  * File Name          : freertos.c
  * Description        : Code for freertos applications
  ******************************************************************************
  * @attention
  *
  * <h2><center>&copy; Copyright (c) 2023 STMicroelectronics.
  * All rights reserved.</center></h2>
  *
  * This software component is licensed by ST under Ultimate Liberty license
  * SLA0044, the "License"; You may not use this file except in compliance with
  * the License. You may obtain a copy of the License at:
  *                             www.st.com/SLA0044
  *
  ******************************************************************************
  */
/* USER CODE END Header */

#include "FreeRTOS.h"
#include "task.h"
#include "main.h"

/* Hook prototypes */
void vApplicationTickHook(void);

/* USER CODE BEGIN 3 */
__weak void vApplicationTickHook( void )
{
   /* This function will be called by each tick interrupt if
   configUSE_TICK_HOOK is set to 1 in FreeRTOSConfig.h. User code can be
   added here, but the tick hook is called from an interrupt context, so
   code must not attempt to block, and only the interrupt safe FreeRTOS API
   functions can be used (those that end in FromISR()). */
}
/* USER CODE END 3 */

/************************ (C) COPYRIGHT STMicroelectronics *****END OF FILE****/
